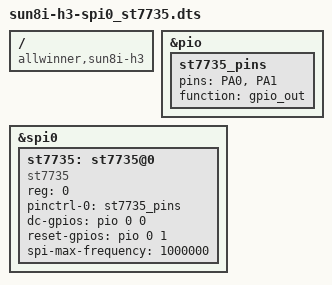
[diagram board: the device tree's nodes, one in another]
/dts-v1/;
/plugin/;

/ {
	compatible = "allwinner,sun8i-h3";

	fragment@0 {
		target = <&pio>;
		__overlay__ {
			st7735_pins: st7735_pins {
				pins = "PA0", "PA1";
				function = "gpio_out";
			};
		};
	};

	fragment@1 {
		target = <&spi0>;
		__overlay__ {
			#address-cells = <1>;
			#size-cells = <0>;

			st7735: st7735@0 {
				compatible = "st7735";
				reg = <0>;
				pinctrl-names = "default";
				pinctrl-0 = <&st7735_pins>;
				
				dc-gpios = <&pio 0 0 0>; /* PA0 */
				reset-gpios = <&pio 0 1 0>; /* PA1 */

				spi-max-frequency = <1000000>;
				status = "okay"; 				
			};
		};
	};
};
